# GD32VW553x register map
File version: 1.0
CPU: other RISC-V, little endian, no MPU, FPU
Registers are 32-bit, read-write, reset 0x0 unless marked. A register's access mark holds for its fields unless they carry their own. Offsets are from the block's base; [hi:lo] are bit positions; {n}, {i} and the like mark numbered series.

## HAU — Hash Acceleration Unit
Base 0x4C060400
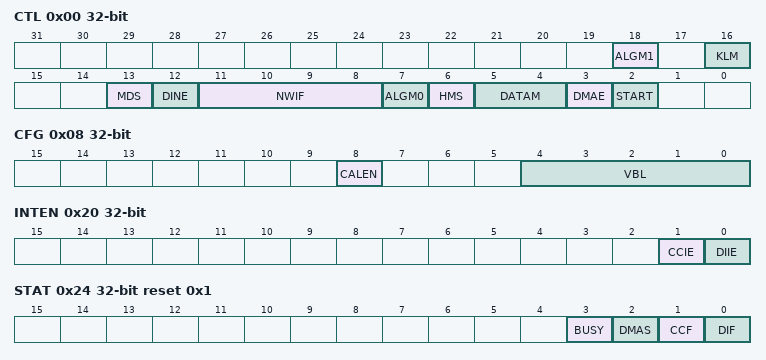
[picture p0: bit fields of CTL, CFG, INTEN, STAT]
0x00 CTL — HAU control register
  [18] ALGM1 — Algorithm selection bit 1
  [16] KLM — Key length mode
  [13] MDS — Multiple DMA Selection
  [12] DINE — DI register not empty
  [11:8] NWIF — Number of words in the input FIFO
  [7] ALGM0 — Algorithm selection bit 0
  [6] HMS — HAU mode selection, must be changed when no computation is processing
  [5:4] DATAM — Data type mode
  [3] DMAE — DMA enable
  [2] START — Start the digest calculation
0x04 DI — HAU data input register
  [31:0] DI — Message data input
0x08 CFG ro — HAU configuration register
  [8] CALEN — Digest calculation enable
  [4:0] VBL — Valid bits length in the last word
{0xC+4i} DO{i} ro (i=0..4) — HAU data output register {i}
  [31:0] DO{i} — Messagedigest result of hash algorithm
0x20 INTEN — HAU interrupt enable register
  [1] CCIE — Calculation completion interrupt enable
  [0] DIIE — Data input interrupt enable
0x24 STAT reset 0x1 — HAU status and flag register
  [3] BUSY — Busy bit
  [2] DMAS — DMA status
  [1] CCF — Digest calculation completion flag
  [0] DIF — Data input flag
0xF8 CTXS0 reset 0x2 — Context switch register 0
  [31:0] CTXx — The complete internal status of the HAU core
{0xF8+4i} CTXS{i} (i=1..53) — Context switch register {i}
  [31:0] CTXx — The complete internal status of the HAU core
{0x310+4i} DO{i} ro (i=5..7) — HAU data output register {i}
  [31:0] DO{i} — Messagedigest result of hash algorithm

## PKCAU — Public Key Cryptographic Acceleration Unit
Base 0x4C061000
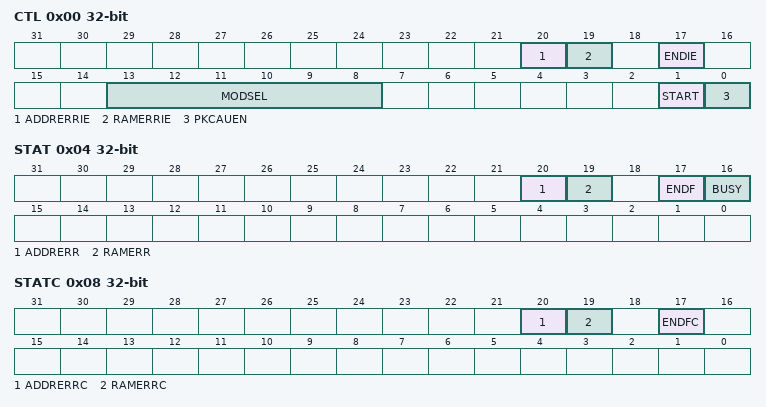
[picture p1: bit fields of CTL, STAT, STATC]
0x00 CTL — Control register
  [20] ADDRERRIE — Address error interrupt enable
  [19] RAMERRIE — RAM error interrupt enable
  [17] ENDIE — End of operation interrupt enable
  [13:8] MODSEL — PKCAU operation mode selection
  [1] START — PKCAU starts operation
  [0] PKCAUEN — PKCAU enable
0x04 STAT ro — Status register
  [20] ADDRERR — Address error
  [19] RAMERR — PKCAU RAM error
  [17] ENDF — End of PKCAU operation
  [16] BUSY — Busy flag
0x08 STATC wo — Status clear register
  [20] ADDRERRC — Address error flag clear
  [19] RAMERRC — PKCAU RAM error flag clear
  [17] ENDFC — End of PKCAU operation flag clear

## QSPI — Quad-SPI interface
Base 0x40025800
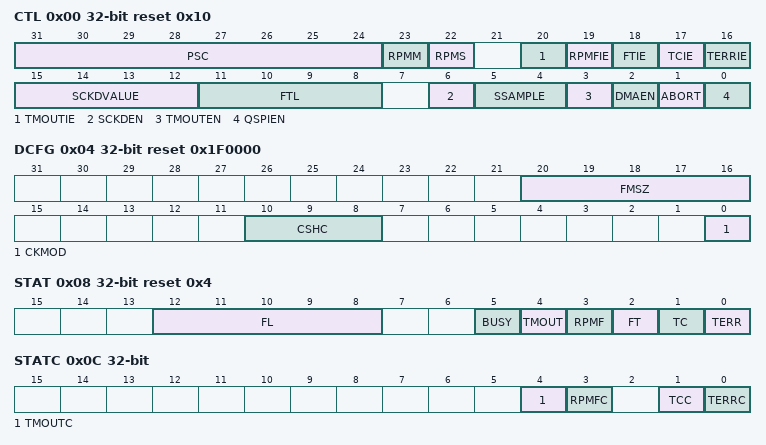
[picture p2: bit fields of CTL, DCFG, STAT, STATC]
0x00 CTL access per field reset 0x10 — Control register
  [31:24] PSC rw — The clock prescaler of AHB clock for generating SCK
  [23] RPMM rw — Read polling match mode
  [22] RPMS rw — Read polling mode stop
  [20] TMOUTIE rw — Timeout interrupt enable
  [19] RPMFIE rw — Read polling mode match interrupt enable
  [18] FTIE rw — FIFO threshold interrupt enable
  [17] TCIE rw — Transfer complete interrupt enable
  [16] TERRIE rw — Transfer error interrupt enable
  [15:12] SCKDVALUE rw — SCK delay value
  [11:8] FTL rw — FIFO threshold level
  [6] SCKDEN rw — SCK delay enable when read data from flash, it is only useful when SSAMPLE is 1
  [5:4] SSAMPLE rw — Sample delay
  [3] TMOUTEN rw — Timeout counter enable
  [2] DMAEN rw — DMA enable
  [1] ABORT wo — Abort request
  [0] QSPIEN rw — the QSPI enable
0x04 DCFG reset 0x1F0000 — Device configuration register
  [20:16] FMSZ — Flash memory size
  [10:8] CSHC — Chip select high cycle
  [0] CKMOD — This bit indicates the SCK level when QSPI is free
0x08 STAT access per field reset 0x4 — Status register
  [12:8] FL rw — FIFO level
  [5] BUSY ro — Busy flag
  [4] TMOUT ro — Timeout flag
  [3] RPMF ro — Read polling match flag
  [2] FT ro — FIFO threshold flag
  [1] TC ro — Transfer complete flag
  [0] TERR ro — Transfer error flag
0x0C STATC wo — Status clear register
  [4] TMOUTC — Clear timeout flag
  [3] RPMFC — Clear read polling mode match flag
  [1] TCC — Clear transfer complete flag
  [0] TERRC — Clear transfer error flag
0x10 DTLEN — Data length register
  [31:0] DTLEN — Data length
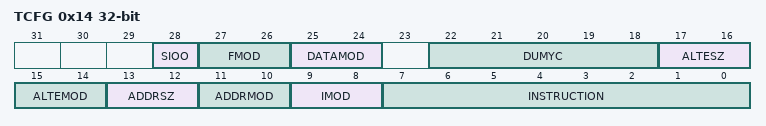
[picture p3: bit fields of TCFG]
0x14 TCFG — Transfer configuration register
  [28] SIOO — Send instruction only once mode
  [27:26] FMOD — Functional mode
  [25:24] DATAMOD — Data mode
  [22:18] DUMYC — Number of dummy cycles
  [17:16] ALTESZ — Alternate bytes size
  [15:14] ALTEMOD — Alternate bytes mode
  [13:12] ADDRSZ — Address size
  [11:10] ADDRMOD — Address mode
  [9:8] IMOD — Instruction mode
  [7:0] INSTRUCTION
0x18 ADDR — Address register
  [31:0] ADDR — Address to be send to the external Flash memory
0x1C ALTE — Alternate bytes register
  [31:0] ALTE — Alternate Bytes
0x20 DATA
  [31:0] DATA — Data that will be interacting with flash memory
0x24 STATMK — Status mask register
  [31:0] MASK — Status mask in read polling mode
0x28 STATMATCH — Status match register
  [31:0] MATCH — Status match in read polling mode
0x2C INTERVAL
  [15:0] INTERVAL — Interval cycle
0x30 TMOUT — Timeout register
  [15:0] TMOUTCYC — Timeout cycle
0x34 FLUSH wo — FIFO flush register
  [0] FLUSH — Used to flush all qspi interal fifo
